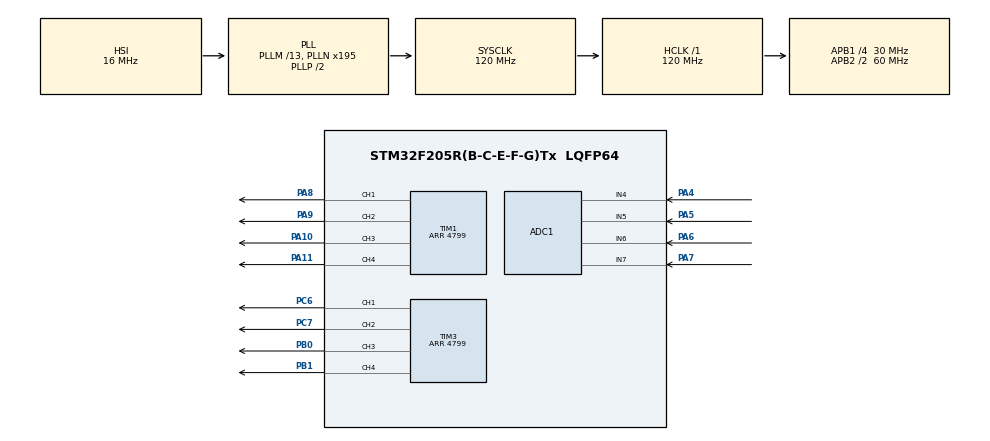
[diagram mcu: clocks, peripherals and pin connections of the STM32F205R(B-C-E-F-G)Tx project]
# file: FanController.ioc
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ADC1.Channel-0\#ChannelRegularConversion=ADC_CHANNEL_4
ADC1.Channel-1\#ChannelRegularConversion=ADC_CHANNEL_5
ADC1.Channel-2\#ChannelRegularConversion=ADC_CHANNEL_6
ADC1.Channel-3\#ChannelRegularConversion=ADC_CHANNEL_7
ADC1.ContinuousConvMode=ENABLE
ADC1.DMAContinuousRequests=ENABLE
ADC1.EOCSelection=ADC_EOC_SEQ_CONV
ADC1.NbrOfConversion=4
ADC1.NbrOfConversionFlag=1
ADC1.Rank-0\#ChannelRegularConversion=1
ADC1.Rank-1\#ChannelRegularConversion=2
ADC1.Rank-2\#ChannelRegularConversion=3
ADC1.Rank-3\#ChannelRegularConversion=4
ADC1.SamplingTime-0\#ChannelRegularConversion=ADC_SAMPLETIME_112CYCLES
ADC1.SamplingTime-1\#ChannelRegularConversion=ADC_SAMPLETIME_112CYCLES
ADC1.SamplingTime-2\#ChannelRegularConversion=ADC_SAMPLETIME_112CYCLES
ADC1.SamplingTime-3\#ChannelRegularConversion=ADC_SAMPLETIME_112CYCLES
ADC1.ScanConvMode=ENABLE
ADC1.master=1
Dma.ADC1.0.Direction=DMA_PERIPH_TO_MEMORY
Dma.ADC1.0.FIFOMode=DMA_FIFOMODE_DISABLE
Dma.ADC1.0.Instance=DMA2_Stream0
Dma.ADC1.0.MemDataAlignment=DMA_MDATAALIGN_WORD
Dma.ADC1.0.MemInc=DMA_MINC_ENABLE
Dma.ADC1.0.Mode=DMA_CIRCULAR
Dma.ADC1.0.PeriphDataAlignment=DMA_PDATAALIGN_WORD
Dma.ADC1.0.PeriphInc=DMA_PINC_DISABLE
Dma.ADC1.0.Priority=DMA_PRIORITY_LOW
Dma.Request0=ADC1
Mcu.Family=STM32F2
Mcu.Name=STM32F205R(B-C-E-F-G)Tx
Mcu.Package=LQFP64
NVIC.DMA2_Stream0_IRQn=true\:0\:0\:false\:false\:true\:false\:true
NVIC.PriorityGroup=NVIC_PRIORITYGROUP_4
PA10.Signal=S_TIM1_CH3
PA11.Signal=S_TIM1_CH4
PA13.Mode=Serial_Wire
PA13.Signal=SYS_JTMS-SWDIO
PA14.Mode=Serial_Wire
PA14.Signal=SYS_JTCK-SWCLK
PA4.Signal=ADCx_IN4
PA5.Signal=ADCx_IN5
PA6.Signal=ADCx_IN6
PA7.Signal=ADCx_IN7
PA8.Signal=S_TIM1_CH1
PA9.Signal=S_TIM1_CH2
PB0.Signal=S_TIM3_CH3
PB1.Signal=S_TIM3_CH4
PC6.Signal=S_TIM3_CH1
PC7.Signal=S_TIM3_CH2
ProjectManager.HeapSize=0x200
ProjectManager.StackSize=0x400
ProjectManager.TargetToolchain=STM32CubeIDE
RCC.48MHZClocksFreq_Value=60000000
RCC.AHBFreq_Value=120000000
RCC.APB1CLKDivider=RCC_HCLK_DIV4
RCC.APB1Freq_Value=30000000
RCC.APB1TimFreq_Value=60000000
RCC.APB2CLKDivider=RCC_HCLK_DIV2
RCC.APB2Freq_Value=60000000
RCC.APB2TimFreq_Value=120000000
RCC.CortexFreq_Value=120000000
RCC.HCLKFreq_Value=120000000
RCC.HSE_VALUE=25000000
RCC.HSI_VALUE=16000000
RCC.LSE_VALUE=32768
RCC.PLLM=13
RCC.PLLN=195
RCC.SYSCLKFreq_VALUE=120000000
RCC.SYSCLKSource=RCC_SYSCLKSOURCE_PLLCLK
RCC.VCOOutputFreq_Value=240000000
SH.ADCx_IN4.0=ADC1_IN4,IN4
SH.ADCx_IN5.0=ADC1_IN5,IN5
SH.ADCx_IN6.0=ADC1_IN6,IN6
SH.ADCx_IN7.0=ADC1_IN7,IN7
SH.S_TIM1_CH1.0=TIM1_CH1,PWM Generation1 CH1
SH.S_TIM1_CH2.0=TIM1_CH2,PWM Generation2 CH2
SH.S_TIM1_CH3.0=TIM1_CH3,PWM Generation3 CH3
SH.S_TIM1_CH4.0=TIM1_CH4,PWM Generation4 CH4
SH.S_TIM3_CH1.0=TIM3_CH1,PWM Generation1 CH1
SH.S_TIM3_CH2.0=TIM3_CH2,PWM Generation2 CH2
SH.S_TIM3_CH3.0=TIM3_CH3,PWM Generation3 CH3
SH.S_TIM3_CH4.0=TIM3_CH4,PWM Generation4 CH4
TIM1.Channel-PWM\ Generation1\ CH1=TIM_CHANNEL_1
TIM1.Channel-PWM\ Generation2\ CH2=TIM_CHANNEL_2
TIM1.Channel-PWM\ Generation3\ CH3=TIM_CHANNEL_3
TIM1.Channel-PWM\ Generation4\ CH4=TIM_CHANNEL_4
TIM1.Period=4799
TIM1.Pulse-PWM\ Generation1\ CH1=1
TIM1.Pulse-PWM\ Generation2\ CH2=10
TIM1.Pulse-PWM\ Generation3\ CH3=100
TIM1.Pulse-PWM\ Generation4\ CH4=1000
TIM3.Channel-PWM\ Generation1\ CH1=TIM_CHANNEL_1
TIM3.Channel-PWM\ Generation2\ CH2=TIM_CHANNEL_2
TIM3.Channel-PWM\ Generation3\ CH3=TIM_CHANNEL_3
TIM3.Channel-PWM\ Generation4\ CH4=TIM_CHANNEL_4
TIM3.Period=4799
TIM3.Pulse-PWM\ Generation1\ CH1=1
TIM3.Pulse-PWM\ Generation2\ CH2=10
TIM3.Pulse-PWM\ Generation3\ CH3=100
TIM3.Pulse-PWM\ Generation4\ CH4=1000
VP_TIM1_VS_ClockSourceINT.Mode=Internal
VP_TIM3_VS_ClockSourceINT.Mode=Internal
board=custom

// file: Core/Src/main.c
/* USER CODE BEGIN Header */
/**
  ******************************************************************************
  * @file           : main.c
  * @brief          : Main program body
  ******************************************************************************
  * @attention
  *
  * <h2><center>&copy; Copyright (c) 2020 STMicroelectronics.
  * All rights reserved.</center></h2>
  *
  * This software component is licensed by ST under BSD 3-Clause license,
  * the "License"; You may not use this file except in compliance with the
  * License. You may obtain a copy of the License at:
  *                        opensource.org/licenses/BSD-3-Clause
  *
  ******************************************************************************
  */
/* USER CODE END Header */
#include "main.h"
#include "adc.h"
#include "dma.h"
#include "tim.h"
#include "gpio.h"

/* USER CODE BEGIN PV */
uint32_t ADC_Data[4];
/* USER CODE END PV */

void SystemClock_Config(void);

int main(void)
{

  /* MCU Configuration--------------------------------------------------------*/

  /* Reset of all peripherals, Initializes the Flash interface and the Systick. */
  HAL_Init();

  /* Configure the system clock */
  SystemClock_Config();

  /* Initialize all configured peripherals */
  MX_GPIO_Init();
  MX_DMA_Init();
  MX_ADC1_Init();
  MX_TIM1_Init();
  MX_TIM3_Init();
  /* USER CODE BEGIN 2 */

  HAL_TIM_PWM_Start(&htim1, TIM_CHANNEL_1);
  HAL_TIM_PWM_Start(&htim1, TIM_CHANNEL_2);
  HAL_TIM_PWM_Start(&htim1, TIM_CHANNEL_3);
  HAL_TIM_PWM_Start(&htim1, TIM_CHANNEL_4);
  HAL_TIM_PWM_Start(&htim3, TIM_CHANNEL_1);
  HAL_TIM_PWM_Start(&htim3, TIM_CHANNEL_2);
  HAL_TIM_PWM_Start(&htim3, TIM_CHANNEL_3);
  HAL_TIM_PWM_Start(&htim3, TIM_CHANNEL_4);

  //HAL_ADC_Start(&hadc1);

  HAL_ADC_Start_DMA(&hadc1, ADC_Data, 4);

  /* USER CODE END 2 */

  /* Infinite loop */
  /* USER CODE BEGIN WHILE */
  while (1)
  {

	  TIM1->CCR1 = ADC_Data[0];
	  TIM1->CCR2 = ADC_Data[1];
	  TIM1->CCR3 = ADC_Data[2];
	  TIM1->CCR4 = ADC_Data[3];
    /* USER CODE END WHILE */

  }
}

void SystemClock_Config(void)
{
  RCC_OscInitTypeDef RCC_OscInitStruct = {0};
  RCC_ClkInitTypeDef RCC_ClkInitStruct = {0};

  /** Initializes the RCC Oscillators according to the specified parameters
  * in the RCC_OscInitTypeDef structure.
  */
  RCC_OscInitStruct.OscillatorType = RCC_OSCILLATORTYPE_HSI;
  RCC_OscInitStruct.HSIState = RCC_HSI_ON;
  RCC_OscInitStruct.HSICalibrationValue = RCC_HSICALIBRATION_DEFAULT;
  RCC_OscInitStruct.PLL.PLLState = RCC_PLL_ON;
  RCC_OscInitStruct.PLL.PLLSource = RCC_PLLSOURCE_HSI;
  RCC_OscInitStruct.PLL.PLLM = 13;
  RCC_OscInitStruct.PLL.PLLN = 195;
  RCC_OscInitStruct.PLL.PLLP = RCC_PLLP_DIV2;
  RCC_OscInitStruct.PLL.PLLQ = 4;
  if (HAL_RCC_OscConfig(&RCC_OscInitStruct) != HAL_OK)
  {
    Error_Handler();
  }
  /** Initializes the CPU, AHB and APB buses clocks
  */
  RCC_ClkInitStruct.ClockType = RCC_CLOCKTYPE_HCLK|RCC_CLOCKTYPE_SYSCLK
                              |RCC_CLOCKTYPE_PCLK1|RCC_CLOCKTYPE_PCLK2;
  RCC_ClkInitStruct.SYSCLKSource = RCC_SYSCLKSOURCE_PLLCLK;
  RCC_ClkInitStruct.AHBCLKDivider = RCC_SYSCLK_DIV1;
  RCC_ClkInitStruct.APB1CLKDivider = RCC_HCLK_DIV4;
  RCC_ClkInitStruct.APB2CLKDivider = RCC_HCLK_DIV2;

  if (HAL_RCC_ClockConfig(&RCC_ClkInitStruct, FLASH_LATENCY_3) != HAL_OK)
  {
    Error_Handler();
  }
}

void Error_Handler(void)
{
}

/************************ (C) COPYRIGHT STMicroelectronics *****END OF FILE****/
